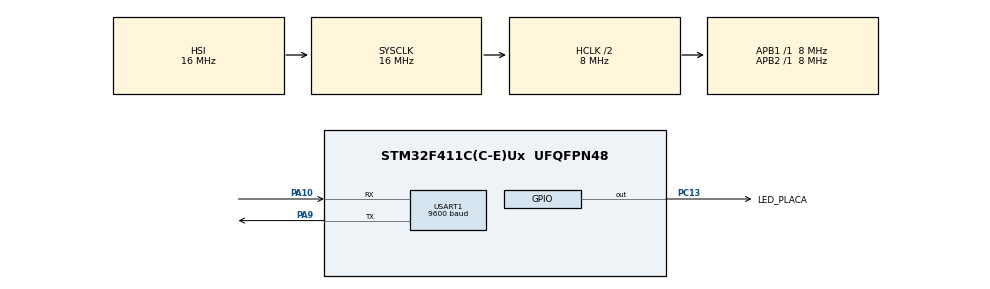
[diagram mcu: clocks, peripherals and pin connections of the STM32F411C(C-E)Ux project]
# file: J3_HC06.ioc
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Mcu.Family=STM32F4
Mcu.Name=STM32F411C(C-E)Ux
Mcu.Package=UFQFPN48
NVIC.PriorityGroup=NVIC_PRIORITYGROUP_4
NVIC.USART1_IRQn=true\:0\:0\:false\:false\:true\:true\:true\:true
PA10.Mode=Asynchronous
PA10.Signal=USART1_RX
PA13.Mode=Serial_Wire
PA13.Signal=SYS_JTMS-SWDIO
PA14.Mode=Serial_Wire
PA14.Signal=SYS_JTCK-SWCLK
PA9.Mode=Asynchronous
PA9.Signal=USART1_TX
PC13-ANTI_TAMP.GPIO_Label=LED_PLACA
PC13-ANTI_TAMP.GPIO_ModeDefaultOutputPP=GPIO_MODE_OUTPUT_PP
PC13-ANTI_TAMP.PinState=GPIO_PIN_RESET
PC13-ANTI_TAMP.Signal=GPIO_Output
PH0\ -\ OSC_IN.Mode=HSE-External-Oscillator
PH0\ -\ OSC_IN.Signal=RCC_OSC_IN
PH1\ -\ OSC_OUT.Mode=HSE-External-Oscillator
PH1\ -\ OSC_OUT.Signal=RCC_OSC_OUT
ProjectManager.HeapSize=0x200
ProjectManager.StackSize=0x400
ProjectManager.TargetToolchain=STM32CubeIDE
RCC.AHBCLKDivider=RCC_SYSCLK_DIV2
RCC.AHBFreq_Value=8000000
RCC.APB1Freq_Value=8000000
RCC.APB1TimFreq_Value=8000000
RCC.APB2Freq_Value=8000000
RCC.APB2TimFreq_Value=8000000
RCC.CortexFreq_Value=8000000
RCC.HCLKFreq_Value=8000000
RCC.HSE_VALUE=25000000
RCC.HSI_VALUE=16000000
RCC.LSE_VALUE=32768
RCC.SYSCLKFreq_VALUE=16000000
RCC.VCOOutputFreq_Value=192000000
USART1.BaudRate=9600
USART1.VirtualMode=VM_ASYNC
board=custom

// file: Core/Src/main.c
/* USER CODE BEGIN Header */
/**
  ******************************************************************************
  * @file           : main.c
  * @brief          : Main program body
  ******************************************************************************
  * @attention
  *
  * Copyright (c) 2022 STMicroelectronics.
  * All rights reserved.
  *
  * This software is licensed under terms that can be found in the LICENSE file
  * in the root directory of this software component.
  * If no LICENSE file comes with this software, it is provided AS-IS.
  *
  ******************************************************************************
  */
/* USER CODE END Header */
#include "main.h"
#include "usart.h"
#include "gpio.h"

/* USER CODE BEGIN Includes */
#include <usr/J3_HC06.h>
/* USER CODE END Includes */

void SystemClock_Config(void);

/* USER CODE BEGIN 0 */
THC06* dispositivoBt;
/* USER CODE END 0 */

int main(void)
{
  /* USER CODE BEGIN 1 */
  uint32_t ledPlaca_delay = 1000;

  /* USER CODE END 1 */

  /* MCU Configuration--------------------------------------------------------*/

  /* Reset of all peripherals, Initializes the Flash interface and the Systick. */
  HAL_Init();

  /* Configure the system clock */
  SystemClock_Config();

  /* Initialize all configured peripherals */
  MX_GPIO_Init();
  MX_USART1_UART_Init();
  /* USER CODE BEGIN 2 */

  HAL_Delay(100); // Estabilizar a UART apos iniciar

  dispositivoBt = J3_HC06_new(&huart1, "J3-Receiver2");
  if (J3_HC06_ini(dispositivoBt))
    {
      ledPlaca_delay = 200;
    }

  /* USER CODE END 2 */

  /* Infinite loop */
  while (1)
  {

    /* USER CODE BEGIN 3 */
	HAL_GPIO_TogglePin(LED_PLACA_GPIO_Port,LED_PLACA_Pin);
	HAL_Delay(ledPlaca_delay);

	if(dispositivoBt->busy)
	{
	    /* Criar um componente Protocolo */
	    /* Passar o buffer recebido para o Protocolo */
	    /* Limpar o buffer de recebimento */
	    /* Ativara  Interrupçao novamente */
	    /* */
	}

	//if(J3_HC06_statusOK(dispositivoBt))
	//{
	  //ledPlaca_delay = 300;
	//}

//	if(J3_HC06_statusOK(dispositivoBt))
//	{
	  //ledPlaca_delay = 100;
	//}
	//else
	//{
	 // HAL_UART_DeInit(&huart1);
	 // huart1.Init.BaudRate = 9600;
	//  if (HAL_UART_Init(&huart1) != HAL_OK) {
	//      Error_Handler();
		//ledPlaca_delay = 5000;
	 //}
	//}

  }
  /* USER CODE END 3 */
}

void SystemClock_Config(void)
{
  RCC_OscInitTypeDef RCC_OscInitStruct = {0};
  RCC_ClkInitTypeDef RCC_ClkInitStruct = {0};

  /** Configure the main internal regulator output voltage
  */
  __HAL_RCC_PWR_CLK_ENABLE();
  __HAL_PWR_VOLTAGESCALING_CONFIG(PWR_REGULATOR_VOLTAGE_SCALE1);

  /** Initializes the RCC Oscillators according to the specified parameters
  * in the RCC_OscInitTypeDef structure.
  */
  RCC_OscInitStruct.OscillatorType = RCC_OSCILLATORTYPE_HSI;
  RCC_OscInitStruct.HSIState = RCC_HSI_ON;
  RCC_OscInitStruct.HSICalibrationValue = RCC_HSICALIBRATION_DEFAULT;
  RCC_OscInitStruct.PLL.PLLState = RCC_PLL_NONE;
  if (HAL_RCC_OscConfig(&RCC_OscInitStruct) != HAL_OK)
  {
    Error_Handler();
  }

  /** Initializes the CPU, AHB and APB buses clocks
  */
  RCC_ClkInitStruct.ClockType = RCC_CLOCKTYPE_HCLK|RCC_CLOCKTYPE_SYSCLK
                              |RCC_CLOCKTYPE_PCLK1|RCC_CLOCKTYPE_PCLK2;
  RCC_ClkInitStruct.SYSCLKSource = RCC_SYSCLKSOURCE_HSI;
  RCC_ClkInitStruct.AHBCLKDivider = RCC_SYSCLK_DIV2;
  RCC_ClkInitStruct.APB1CLKDivider = RCC_HCLK_DIV1;
  RCC_ClkInitStruct.APB2CLKDivider = RCC_HCLK_DIV1;

  if (HAL_RCC_ClockConfig(&RCC_ClkInitStruct, FLASH_LATENCY_0) != HAL_OK)
  {
    Error_Handler();
  }
}

/* USER CODE BEGIN 4 */
void HAL_UART_RxCpltCallback(UART_HandleTypeDef *UartHandle)
{
  if(UartHandle->Instance == dispositivoBt->uart->Instance)
  {
    dispositivoBt->busy = true;
  }
}
/* USER CODE END 4 */

void Error_Handler(void)
{
  __disable_irq();
  while (1)
  {
  }
}
